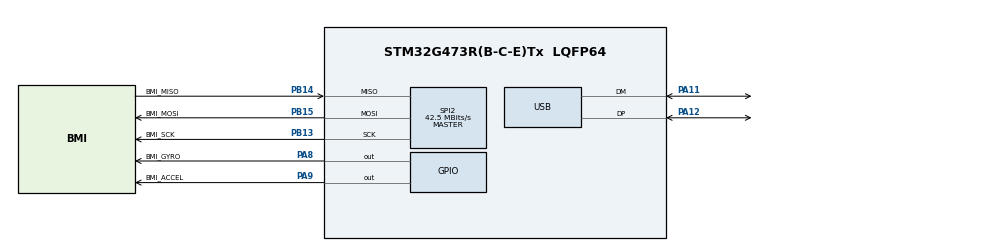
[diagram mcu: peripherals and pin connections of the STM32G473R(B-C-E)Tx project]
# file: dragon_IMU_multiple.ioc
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Mcu.Family=STM32G4
Mcu.Name=STM32G473R(B-C-E)Tx
Mcu.Package=LQFP64
NVIC.PriorityGroup=NVIC_PRIORITYGROUP_4
NVIC.USB_LP_IRQn=true\:0\:0\:false\:false\:true\:false\:true\:true
PA11.Mode=Device
PA11.Signal=USB_DM
PA12.Mode=Device
PA12.Signal=USB_DP
PA13.Mode=Serial_Wire
PA13.Signal=SYS_JTMS-SWDIO
PA14.Mode=Serial_Wire
PA14.Signal=SYS_JTCK-SWCLK
PA8.GPIO_Label=BMI_GYRO
PA8.Signal=GPIO_Output
PA9.GPIO_Label=BMI_ACCEL
PA9.Signal=GPIO_Output
PB13.GPIO_Label=BMI_SCK
PB13.Mode=Full_Duplex_Master
PB13.Signal=SPI2_SCK
PB14.GPIO_Label=BMI_MISO
PB14.Mode=Full_Duplex_Master
PB14.Signal=SPI2_MISO
PB15.GPIO_Label=BMI_MOSI
PB15.Mode=Full_Duplex_Master
PB15.Signal=SPI2_MOSI
PF0-OSC_IN.Mode=HSE-External-Oscillator
PF0-OSC_IN.Signal=RCC_OSC_IN
PF1-OSC_OUT.Mode=HSE-External-Oscillator
PF1-OSC_OUT.Signal=RCC_OSC_OUT
ProjectManager.HeapSize=0x200
ProjectManager.StackSize=0x400
ProjectManager.TargetToolchain=MDK-ARM V5.32
RCC.ADC12Freq_Value=170000000
RCC.ADC345Freq_Value=170000000
RCC.AHBFreq_Value=170000000
RCC.APB1Freq_Value=170000000
RCC.APB1TimFreq_Value=170000000
RCC.APB2Freq_Value=170000000
RCC.APB2TimFreq_Value=170000000
RCC.CK48CLockSelection=RCC_USBCLKSOURCE_HSI48
RCC.CortexFreq_Value=170000000
RCC.EXTERNAL_CLOCK_VALUE=12288000
RCC.HCLKFreq_Value=170000000
RCC.HSE_VALUE=24000000
RCC.HSI48_VALUE=48000000
RCC.HSI_VALUE=16000000
RCC.LSE_VALUE=32768
RCC.PLLM=RCC_PLLM_DIV6
RCC.PLLN=85
RCC.PLLQ=RCC_PLLQ_DIV4
RCC.PLLSourceVirtual=RCC_PLLSOURCE_HSE
RCC.SYSCLKFreq_VALUE=170000000
RCC.SYSCLKSource=RCC_SYSCLKSOURCE_PLLCLK
RCC.USBFreq_Value=48000000
RCC.VCOOutputFreq_Value=340000000
SPI2.BaudRatePrescaler=SPI_BAUDRATEPRESCALER_4
SPI2.CalculateBaudRate=42.5 MBits/s
SPI2.Direction=SPI_DIRECTION_2LINES
SPI2.Mode=SPI_MODE_MASTER
SPI2.VirtualType=VM_MASTER
USB_DEVICE.APP_RX_DATA_SIZE=64
USB_DEVICE.APP_TX_DATA_SIZE=64
USB_DEVICE.CLASS_NAME_FS=CDC
USB_DEVICE.VirtualMode=Cdc
USB_DEVICE.VirtualModeFS=Cdc_FS
VP_SYS_VS_DBSignals.Mode=DisableDeadBatterySignals
VP_USB_DEVICE_VS_USB_DEVICE_CDC_FS.Mode=CDC_FS
board=custom

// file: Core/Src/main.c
/* USER CODE BEGIN Header */
/**
  ******************************************************************************
  * @file           : main.c
  * @brief          : Main program body
  ******************************************************************************
  * @attention
  *
  * Copyright (c) 2025 STMicroelectronics.
  * All rights reserved.
  *
  * This software is licensed under terms that can be found in the LICENSE file
  * in the root directory of this software component.
  * If no LICENSE file comes with this software, it is provided AS-IS.
  *
  ******************************************************************************
  */
/* USER CODE END Header */
#include "main.h"
#include "spi.h"
#include "usb_device.h"
#include "gpio.h"

/* USER CODE BEGIN Includes */
#include "usbd_cdc_if.h"
uint8_t usb_tx_data[8]={0};
uint8_t usb_rx_data[64]={0};
uint32_t usb_rx_all_length=0;
/* USER CODE END Includes */

void SystemClock_Config(void);

int main(void)
{

  /* MCU Configuration--------------------------------------------------------*/

  /* Reset of all peripherals, Initializes the Flash interface and the Systick. */
  HAL_Init();

  /* Configure the system clock */
  SystemClock_Config();

  /* Initialize all configured peripherals */
  MX_GPIO_Init();
  MX_USB_Device_Init();
  MX_SPI2_Init();

  /* Infinite loop */
  while (1)
  {

    /* USER CODE BEGIN 3 */

//CDC_Transmit_FS(usb_tx_data,8);
//		LL_mDelay(100);
  }
  /* USER CODE END 3 */
}

void SystemClock_Config(void)
{
  LL_FLASH_SetLatency(LL_FLASH_LATENCY_4);
  while(LL_FLASH_GetLatency() != LL_FLASH_LATENCY_4)
  {
  }
  LL_PWR_EnableRange1BoostMode();
  LL_RCC_HSE_Enable();
   /* Wait till HSE is ready */
  while(LL_RCC_HSE_IsReady() != 1)
  {
  }

  LL_RCC_HSI48_Enable();
   /* Wait till HSI48 is ready */
  while(LL_RCC_HSI48_IsReady() != 1)
  {
  }

  LL_RCC_PLL_ConfigDomain_SYS(LL_RCC_PLLSOURCE_HSE, LL_RCC_PLLM_DIV_6, 85, LL_RCC_PLLR_DIV_2);
  LL_RCC_PLL_EnableDomain_SYS();
  LL_RCC_PLL_Enable();
   /* Wait till PLL is ready */
  while(LL_RCC_PLL_IsReady() != 1)
  {
  }

  LL_RCC_SetSysClkSource(LL_RCC_SYS_CLKSOURCE_PLL);
  LL_RCC_SetAHBPrescaler(LL_RCC_SYSCLK_DIV_2);
   /* Wait till System clock is ready */
  while(LL_RCC_GetSysClkSource() != LL_RCC_SYS_CLKSOURCE_STATUS_PLL)
  {
  }

  /* Insure 1us transition state at intermediate medium speed clock*/
  for (__IO uint32_t i = (170 >> 1); i !=0; i--);

  /* Set AHB prescaler*/
  LL_RCC_SetAHBPrescaler(LL_RCC_SYSCLK_DIV_1);
  LL_RCC_SetAPB1Prescaler(LL_RCC_APB1_DIV_1);
  LL_RCC_SetAPB2Prescaler(LL_RCC_APB2_DIV_1);
  LL_SetSystemCoreClock(170000000);

   /* Update the time base */
  if (HAL_InitTick (TICK_INT_PRIORITY) != HAL_OK)
  {
    Error_Handler();
  }
}

void Error_Handler(void)
{
  __disable_irq();
  while (1)
  {
  }
}
